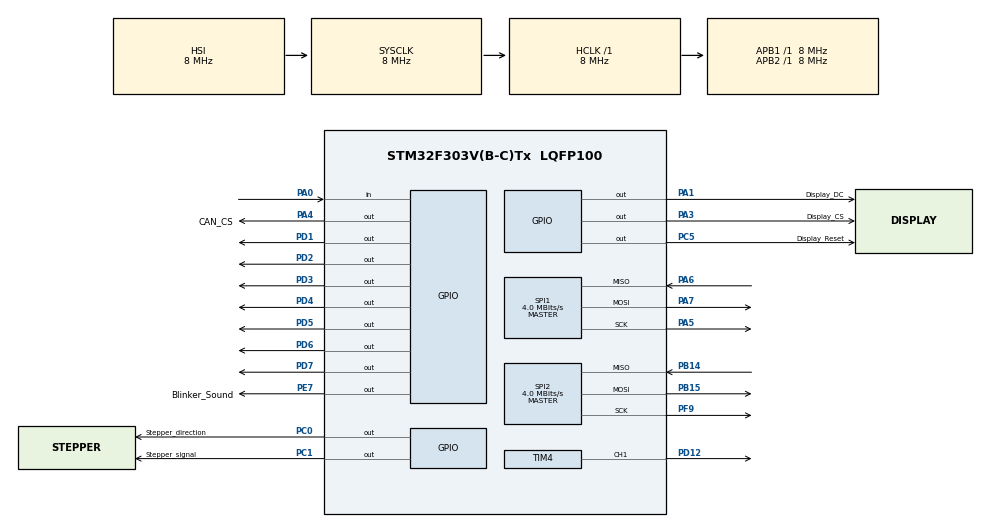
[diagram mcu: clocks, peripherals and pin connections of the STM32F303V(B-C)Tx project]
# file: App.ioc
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Mcu.Family=STM32F3
Mcu.Name=STM32F303V(B-C)Tx
Mcu.Package=LQFP100
NVIC.PriorityGroup=NVIC_PRIORITYGROUP_4
NVIC.TIM2_IRQn=true\:0\:0\:false\:false\:true\:true\:true
NVIC.TIM3_IRQn=true\:0\:0\:false\:false\:true\:true\:true
NVIC.TIM4_IRQn=true\:0\:0\:false\:false\:true\:true\:true
NVIC.TIM7_IRQn=true\:0\:0\:false\:false\:true\:true\:true
PA0.Signal=GPIO_Input
PA1.GPIO_Label=Display_DC
PA1.GPIO_Speed=GPIO_SPEED_FREQ_HIGH
PA1.Signal=GPIO_Output
PA3.GPIO_Label=Display_CS
PA3.GPIO_Speed=GPIO_SPEED_FREQ_HIGH
PA3.Signal=GPIO_Output
PA4.GPIO_Label=CAN_CS
PA4.GPIO_Speed=GPIO_SPEED_FREQ_HIGH
PA4.Signal=GPIO_Output
PA5.Mode=Full_Duplex_Master
PA5.Signal=SPI1_SCK
PA6.Mode=Full_Duplex_Master
PA6.Signal=SPI1_MISO
PA7.Mode=Full_Duplex_Master
PA7.Signal=SPI1_MOSI
PB14.Mode=Full_Duplex_Master
PB14.Signal=SPI2_MISO
PB15.Mode=Full_Duplex_Master
PB15.Signal=SPI2_MOSI
PC0.GPIO_Label=Stepper_direction
PC0.Signal=GPIO_Output
PC1.GPIO_Label=Stepper_signal
PC1.Signal=GPIO_Output
PC5.GPIO_Label=Display_Reset
PC5.GPIO_Speed=GPIO_SPEED_FREQ_HIGH
PC5.Signal=GPIO_Output
PD1.Signal=GPIO_Output
PD12.Signal=S_TIM4_CH1
PD2.Signal=GPIO_Output
PD3.Signal=GPIO_Output
PD4.Signal=GPIO_Output
PD5.Signal=GPIO_Output
PD6.Signal=GPIO_Output
PD7.Signal=GPIO_Output
PE7.GPIO_Label=Blinker_Sound
PE7.Signal=GPIO_Output
PF9.Mode=Full_Duplex_Master
PF9.Signal=SPI2_SCK
ProjectManager.HeapSize=0x200
ProjectManager.StackSize=0x400
ProjectManager.TargetToolchain=SW4STM32
RCC.AHBFreq_Value=8000000
RCC.APB1Freq_Value=8000000
RCC.APB2Freq_Value=8000000
RCC.CortexFreq_Value=8000000
RCC.HSE_VALUE=8000000
RCC.HSI_VALUE=8000000
RCC.LSE_VALUE=32768
RCC.SYSCLKFreq_VALUE=8000000
SH.S_TIM4_CH1.0=TIM4_CH1,PWM Generation1 CH1
SPI1.BaudRatePrescaler=SPI_BAUDRATEPRESCALER_2
SPI1.CalculateBaudRate=4.0 MBits/s
SPI1.DataSize=SPI_DATASIZE_8BIT
SPI1.Direction=SPI_DIRECTION_2LINES
SPI1.Mode=SPI_MODE_MASTER
SPI1.NSSPMode=SPI_NSS_PULSE_DISABLE
SPI1.VirtualType=VM_MASTER
SPI2.CalculateBaudRate=4.0 MBits/s
SPI2.DataSize=SPI_DATASIZE_8BIT
SPI2.Direction=SPI_DIRECTION_2LINES
SPI2.Mode=SPI_MODE_MASTER
SPI2.NSSPMode=SPI_NSS_PULSE_DISABLE
SPI2.VirtualType=VM_MASTER
TIM2.Period=5
TIM2.Prescaler=80
TIM3.Period=20
TIM3.Prescaler=800
TIM4.AutoReloadPreload=TIM_AUTORELOAD_PRELOAD_DISABLE
TIM4.Channel-PWM\ Generation1\ CH1=TIM_CHANNEL_1
TIM4.Period=100
TIM4.Prescaler=1
TIM7.Period=1000
TIM7.Prescaler=8000
VP_TIM2_VS_ClockSourceINT.Mode=Internal
VP_TIM3_VS_ClockSourceINT.Mode=Internal
VP_TIM4_VS_ClockSourceINT.Mode=Internal
VP_TIM7_VS_ClockSourceINT.Mode=Enable_Timer
board=custom

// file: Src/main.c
/* USER CODE BEGIN Header */
/**
  ******************************************************************************
  * @file           : main.c
  * @brief          : Main program body
  ******************************************************************************
  * @attention
  *
  * <h2><center>&copy; Copyright (c) 2019 STMicroelectronics.
  * All rights reserved.</center></h2>
  *
  * This software component is licensed by ST under BSD 3-Clause license,
  * the "License"; You may not use this file except in compliance with the
  * License. You may obtain a copy of the License at:
  *                        opensource.org/licenses/BSD-3-Clause
  *
  ******************************************************************************
  */
/* USER CODE END Header */

#include "main.h"

/* USER CODE BEGIN Includes */
#include "user_main.h"
#include "stm32f3xx_hal.h"
#include "CANSPI.h"

#include "ILI9341_STM32_Driver.h"
#include "ILI9341_GFX.h"

#include "snow_tiger.h"
/* USER CODE END Includes */

SPI_HandleTypeDef hspi1;
SPI_HandleTypeDef hspi2;

TIM_HandleTypeDef htim2;
TIM_HandleTypeDef htim3;
TIM_HandleTypeDef htim4;
TIM_HandleTypeDef htim7;

void SystemClock_Config(void);
static void MX_GPIO_Init(void);
static void MX_SPI1_Init(void);
static void MX_TIM3_Init(void);
static void MX_TIM4_Init(void);
static void MX_TIM2_Init(void);
static void MX_TIM7_Init(void);
static void MX_SPI2_Init(void);

int main(void)
{

  /* MCU Configuration--------------------------------------------------------*/

  /* Reset of all peripherals, Initializes the Flash interface and the Systick. */
  HAL_Init();

  /* Configure the system clock */
  SystemClock_Config();

  /* Initialize all configured peripherals */
  MX_GPIO_Init();
  MX_SPI1_Init();
  MX_TIM3_Init();
  MX_TIM4_Init();
  MX_TIM2_Init();
  MX_TIM7_Init();
  MX_SPI2_Init();
  /* USER CODE BEGIN 2 */
  user_setup();
  /* USER CODE END 2 */

  /* Infinite loop */
  while (1)
  {

    /* USER CODE BEGIN 3 */

	  user_loop();
  }
  /* USER CODE END 3 */
}

void SystemClock_Config(void)
{
  RCC_OscInitTypeDef RCC_OscInitStruct = {0};
  RCC_ClkInitTypeDef RCC_ClkInitStruct = {0};

  /** Initializes the CPU, AHB and APB busses clocks
  */
  RCC_OscInitStruct.OscillatorType = RCC_OSCILLATORTYPE_HSI;
  RCC_OscInitStruct.HSIState = RCC_HSI_ON;
  RCC_OscInitStruct.HSICalibrationValue = RCC_HSICALIBRATION_DEFAULT;
  RCC_OscInitStruct.PLL.PLLState = RCC_PLL_NONE;
  if (HAL_RCC_OscConfig(&RCC_OscInitStruct) != HAL_OK)
  {
    Error_Handler();
  }
  /** Initializes the CPU, AHB and APB busses clocks
  */
  RCC_ClkInitStruct.ClockType = RCC_CLOCKTYPE_HCLK|RCC_CLOCKTYPE_SYSCLK
                              |RCC_CLOCKTYPE_PCLK1|RCC_CLOCKTYPE_PCLK2;
  RCC_ClkInitStruct.SYSCLKSource = RCC_SYSCLKSOURCE_HSI;
  RCC_ClkInitStruct.AHBCLKDivider = RCC_SYSCLK_DIV1;
  RCC_ClkInitStruct.APB1CLKDivider = RCC_HCLK_DIV1;
  RCC_ClkInitStruct.APB2CLKDivider = RCC_HCLK_DIV1;

  if (HAL_RCC_ClockConfig(&RCC_ClkInitStruct, FLASH_LATENCY_0) != HAL_OK)
  {
    Error_Handler();
  }
}

static void MX_SPI1_Init(void)
{

  /* SPI1 parameter configuration*/
  hspi1.Instance = SPI1;
  hspi1.Init.Mode = SPI_MODE_MASTER;
  hspi1.Init.Direction = SPI_DIRECTION_2LINES;
  hspi1.Init.DataSize = SPI_DATASIZE_8BIT;
  hspi1.Init.CLKPolarity = SPI_POLARITY_LOW;
  hspi1.Init.CLKPhase = SPI_PHASE_1EDGE;
  hspi1.Init.NSS = SPI_NSS_SOFT;
  hspi1.Init.BaudRatePrescaler = SPI_BAUDRATEPRESCALER_2;
  hspi1.Init.FirstBit = SPI_FIRSTBIT_MSB;
  hspi1.Init.TIMode = SPI_TIMODE_DISABLE;
  hspi1.Init.CRCCalculation = SPI_CRCCALCULATION_DISABLE;
  hspi1.Init.CRCPolynomial = 7;
  hspi1.Init.CRCLength = SPI_CRC_LENGTH_DATASIZE;
  hspi1.Init.NSSPMode = SPI_NSS_PULSE_DISABLE;
  if (HAL_SPI_Init(&hspi1) != HAL_OK)
  {
    Error_Handler();
  }

}

static void MX_SPI2_Init(void)
{

  /* SPI2 parameter configuration*/
  hspi2.Instance = SPI2;
  hspi2.Init.Mode = SPI_MODE_MASTER;
  hspi2.Init.Direction = SPI_DIRECTION_2LINES;
  hspi2.Init.DataSize = SPI_DATASIZE_8BIT;
  hspi2.Init.CLKPolarity = SPI_POLARITY_LOW;
  hspi2.Init.CLKPhase = SPI_PHASE_1EDGE;
  hspi2.Init.NSS = SPI_NSS_SOFT;
  hspi2.Init.BaudRatePrescaler = SPI_BAUDRATEPRESCALER_2;
  hspi2.Init.FirstBit = SPI_FIRSTBIT_MSB;
  hspi2.Init.TIMode = SPI_TIMODE_DISABLE;
  hspi2.Init.CRCCalculation = SPI_CRCCALCULATION_DISABLE;
  hspi2.Init.CRCPolynomial = 7;
  hspi2.Init.CRCLength = SPI_CRC_LENGTH_DATASIZE;
  hspi2.Init.NSSPMode = SPI_NSS_PULSE_DISABLE;
  if (HAL_SPI_Init(&hspi2) != HAL_OK)
  {
    Error_Handler();
  }

}

static void MX_TIM2_Init(void)
{

  TIM_ClockConfigTypeDef sClockSourceConfig = {0};
  TIM_MasterConfigTypeDef sMasterConfig = {0};

  htim2.Instance = TIM2;
  htim2.Init.Prescaler = 80;
  htim2.Init.CounterMode = TIM_COUNTERMODE_UP;
  htim2.Init.Period = 5;
  htim2.Init.ClockDivision = TIM_CLOCKDIVISION_DIV1;
  htim2.Init.AutoReloadPreload = TIM_AUTORELOAD_PRELOAD_DISABLE;
  if (HAL_TIM_Base_Init(&htim2) != HAL_OK)
  {
    Error_Handler();
  }
  sClockSourceConfig.ClockSource = TIM_CLOCKSOURCE_INTERNAL;
  if (HAL_TIM_ConfigClockSource(&htim2, &sClockSourceConfig) != HAL_OK)
  {
    Error_Handler();
  }
  sMasterConfig.MasterOutputTrigger = TIM_TRGO_RESET;
  sMasterConfig.MasterSlaveMode = TIM_MASTERSLAVEMODE_DISABLE;
  if (HAL_TIMEx_MasterConfigSynchronization(&htim2, &sMasterConfig) != HAL_OK)
  {
    Error_Handler();
  }

}

static void MX_TIM3_Init(void)
{

  TIM_ClockConfigTypeDef sClockSourceConfig = {0};
  TIM_MasterConfigTypeDef sMasterConfig = {0};

  htim3.Instance = TIM3;
  htim3.Init.Prescaler = 800;
  htim3.Init.CounterMode = TIM_COUNTERMODE_UP;
  htim3.Init.Period = 20;
  htim3.Init.ClockDivision = TIM_CLOCKDIVISION_DIV1;
  htim3.Init.AutoReloadPreload = TIM_AUTORELOAD_PRELOAD_DISABLE;
  if (HAL_TIM_Base_Init(&htim3) != HAL_OK)
  {
    Error_Handler();
  }
  sClockSourceConfig.ClockSource = TIM_CLOCKSOURCE_INTERNAL;
  if (HAL_TIM_ConfigClockSource(&htim3, &sClockSourceConfig) != HAL_OK)
  {
    Error_Handler();
  }
  sMasterConfig.MasterOutputTrigger = TIM_TRGO_RESET;
  sMasterConfig.MasterSlaveMode = TIM_MASTERSLAVEMODE_DISABLE;
  if (HAL_TIMEx_MasterConfigSynchronization(&htim3, &sMasterConfig) != HAL_OK)
  {
    Error_Handler();
  }

}

static void MX_TIM4_Init(void)
{

  TIM_ClockConfigTypeDef sClockSourceConfig = {0};
  TIM_MasterConfigTypeDef sMasterConfig = {0};
  TIM_OC_InitTypeDef sConfigOC = {0};

  htim4.Instance = TIM4;
  htim4.Init.Prescaler = 1;
  htim4.Init.CounterMode = TIM_COUNTERMODE_UP;
  htim4.Init.Period = 100;
  htim4.Init.ClockDivision = TIM_CLOCKDIVISION_DIV1;
  htim4.Init.AutoReloadPreload = TIM_AUTORELOAD_PRELOAD_DISABLE;
  if (HAL_TIM_Base_Init(&htim4) != HAL_OK)
  {
    Error_Handler();
  }
  sClockSourceConfig.ClockSource = TIM_CLOCKSOURCE_INTERNAL;
  if (HAL_TIM_ConfigClockSource(&htim4, &sClockSourceConfig) != HAL_OK)
  {
    Error_Handler();
  }
  if (HAL_TIM_PWM_Init(&htim4) != HAL_OK)
  {
    Error_Handler();
  }
  sMasterConfig.MasterOutputTrigger = TIM_TRGO_RESET;
  sMasterConfig.MasterSlaveMode = TIM_MASTERSLAVEMODE_DISABLE;
  if (HAL_TIMEx_MasterConfigSynchronization(&htim4, &sMasterConfig) != HAL_OK)
  {
    Error_Handler();
  }
  sConfigOC.OCMode = TIM_OCMODE_PWM1;
  sConfigOC.Pulse = 0;
  sConfigOC.OCPolarity = TIM_OCPOLARITY_HIGH;
  sConfigOC.OCFastMode = TIM_OCFAST_DISABLE;
  if (HAL_TIM_PWM_ConfigChannel(&htim4, &sConfigOC, TIM_CHANNEL_1) != HAL_OK)
  {
    Error_Handler();
  }
  HAL_TIM_MspPostInit(&htim4);

}

static void MX_TIM7_Init(void)
{

  TIM_MasterConfigTypeDef sMasterConfig = {0};

  htim7.Instance = TIM7;
  htim7.Init.Prescaler = 8000;
  htim7.Init.CounterMode = TIM_COUNTERMODE_UP;
  htim7.Init.Period = 1000;
  htim7.Init.AutoReloadPreload = TIM_AUTORELOAD_PRELOAD_DISABLE;
  if (HAL_TIM_Base_Init(&htim7) != HAL_OK)
  {
    Error_Handler();
  }
  sMasterConfig.MasterOutputTrigger = TIM_TRGO_RESET;
  sMasterConfig.MasterSlaveMode = TIM_MASTERSLAVEMODE_DISABLE;
  if (HAL_TIMEx_MasterConfigSynchronization(&htim7, &sMasterConfig) != HAL_OK)
  {
    Error_Handler();
  }

}

static void MX_GPIO_Init(void)
{
  GPIO_InitTypeDef GPIO_InitStruct = {0};

  /* GPIO Ports Clock Enable */
  __HAL_RCC_GPIOF_CLK_ENABLE();
  __HAL_RCC_GPIOC_CLK_ENABLE();
  __HAL_RCC_GPIOA_CLK_ENABLE();
  __HAL_RCC_GPIOE_CLK_ENABLE();
  __HAL_RCC_GPIOB_CLK_ENABLE();
  __HAL_RCC_GPIOD_CLK_ENABLE();

  /*Configure GPIO pin Output Level */
  HAL_GPIO_WritePin(GPIOC, Stepper_direction_Pin|Stepper_signal_Pin|Display_Reset_Pin, GPIO_PIN_RESET);

  /*Configure GPIO pin Output Level */
  HAL_GPIO_WritePin(GPIOA, Display_DC_Pin|Display_CS_Pin|CAN_CS_Pin, GPIO_PIN_RESET);

  /*Configure GPIO pin Output Level */
  HAL_GPIO_WritePin(Blinker_Sound_GPIO_Port, Blinker_Sound_Pin, GPIO_PIN_RESET);

  /*Configure GPIO pin Output Level */
  HAL_GPIO_WritePin(GPIOD, GPIO_PIN_1|GPIO_PIN_2|GPIO_PIN_3|GPIO_PIN_4
                          |GPIO_PIN_5|GPIO_PIN_6|GPIO_PIN_7, GPIO_PIN_RESET);

  /*Configure GPIO pins : Stepper_direction_Pin Stepper_signal_Pin */
  GPIO_InitStruct.Pin = Stepper_direction_Pin|Stepper_signal_Pin;
  GPIO_InitStruct.Mode = GPIO_MODE_OUTPUT_PP;
  GPIO_InitStruct.Pull = GPIO_NOPULL;
  GPIO_InitStruct.Speed = GPIO_SPEED_FREQ_LOW;
  HAL_GPIO_Init(GPIOC, &GPIO_InitStruct);

  /*Configure GPIO pin : PA0 */
  GPIO_InitStruct.Pin = GPIO_PIN_0;
  GPIO_InitStruct.Mode = GPIO_MODE_INPUT;
  GPIO_InitStruct.Pull = GPIO_NOPULL;
  HAL_GPIO_Init(GPIOA, &GPIO_InitStruct);

  /*Configure GPIO pins : Display_DC_Pin Display_CS_Pin CAN_CS_Pin */
  GPIO_InitStruct.Pin = Display_DC_Pin|Display_CS_Pin|CAN_CS_Pin;
  GPIO_InitStruct.Mode = GPIO_MODE_OUTPUT_PP;
  GPIO_InitStruct.Pull = GPIO_NOPULL;
  GPIO_InitStruct.Speed = GPIO_SPEED_FREQ_HIGH;
  HAL_GPIO_Init(GPIOA, &GPIO_InitStruct);

  /*Configure GPIO pin : Display_Reset_Pin */
  GPIO_InitStruct.Pin = Display_Reset_Pin;
  GPIO_InitStruct.Mode = GPIO_MODE_OUTPUT_PP;
  GPIO_InitStruct.Pull = GPIO_NOPULL;
  GPIO_InitStruct.Speed = GPIO_SPEED_FREQ_HIGH;
  HAL_GPIO_Init(Display_Reset_GPIO_Port, &GPIO_InitStruct);

  /*Configure GPIO pin : Blinker_Sound_Pin */
  GPIO_InitStruct.Pin = Blinker_Sound_Pin;
  GPIO_InitStruct.Mode = GPIO_MODE_OUTPUT_PP;
  GPIO_InitStruct.Pull = GPIO_NOPULL;
  GPIO_InitStruct.Speed = GPIO_SPEED_FREQ_LOW;
  HAL_GPIO_Init(Blinker_Sound_GPIO_Port, &GPIO_InitStruct);

  /*Configure GPIO pins : PD1 PD2 PD3 PD4
                           PD5 PD6 PD7 */
  GPIO_InitStruct.Pin = GPIO_PIN_1|GPIO_PIN_2|GPIO_PIN_3|GPIO_PIN_4
                          |GPIO_PIN_5|GPIO_PIN_6|GPIO_PIN_7;
  GPIO_InitStruct.Mode = GPIO_MODE_OUTPUT_PP;
  GPIO_InitStruct.Pull = GPIO_NOPULL;
  GPIO_InitStruct.Speed = GPIO_SPEED_FREQ_LOW;
  HAL_GPIO_Init(GPIOD, &GPIO_InitStruct);

}

void Error_Handler(void)
{
}

/************************ (C) COPYRIGHT STMicroelectronics *****END OF FILE****/
